AUTOSAR XML (schema 00052)
package /apd/AdaptiveApplicationSwComponentTypes
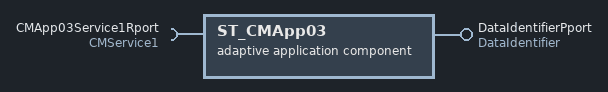
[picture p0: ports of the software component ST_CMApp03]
  adaptive application sw component type ST_CMApp03
    require port CMApp03Service1Rport: required-interface=CMService1
    provide port DataIdentifierPport: provided-interface=DataIdentifier
package /apd/Executables
  executable ST_CMApp03: category=APPLICATION_LEVEL, minimum-timer-granularity=1000.0
    root sw component prototype ST_CMApp03Root: application-type=ST_CMApp03
